# S32R372 register map
Vendor: Freescale Semiconductor, Inc.; Series: Qorivva; File version: 1.6
Registers are 32-bit, read-write, reset 0x0 unless marked. A register's access mark holds for its fields unless they carry their own. Offsets are from the block's base; [hi:lo] are bit positions; 'fields as' and 'values as' point back to an identical list.

## PMC
Base 0xFFFA0400; register names take the prefix PMC_
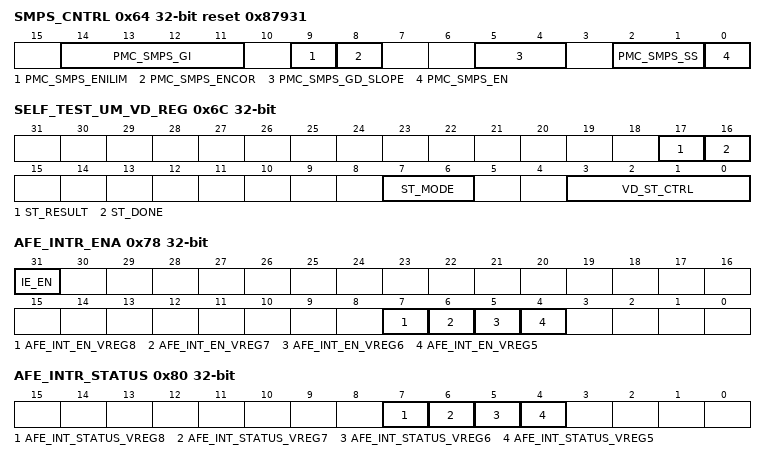
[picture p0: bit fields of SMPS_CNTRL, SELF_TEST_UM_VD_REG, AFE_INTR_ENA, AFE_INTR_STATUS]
0x64 SMPS_CNTRL reset 0x87931 — SMPS Control Register
  [14:11] PMC_SMPS_GI — SMPS Overshoot Current Trimming
  [9] PMC_SMPS_ENILIM — SMPS Inductor Current Limitation Enable
  [8] PMC_SMPS_ENCOR — SMPS Hysteretic Correction Enable
    0=Disabled; 1=Enabled
  [5:4] PMC_SMPS_GD_SLOPE — SMPS gate driver strength
    0=100% drive strength; 1=Approximately 70% drive strength; 2=Approximately 50% drive strength; 3=Approximately 35% drive strength
  [2:1] PMC_SMPS_SS — SMPS spread spectrum control
    0=No modulation; 1=15% modulation; 2=7.5% modulation; 3=30% modulation
  [0] PMC_SMPS_EN — SMPS controller enable
    0=SMPS control is disabled; 1=SMPS control is enabled
0x68 STTW reset 0xA0 — LVD Self Test Time Window Register
  [11:0] STTW — Self Test Time Window.
0x6C SELF_TEST_UM_VD_REG — Voltage Detect User Mode Test Register
  [17] ST_RESULT — ST_RESULT. Self Test result status.
    0=Self Test Failed; 1=Self Test Passed
  [16] ST_DONE ro — Self Test Done status.
    0=Self test running; 1=Self test completed
  [7:6] ST_MODE — Self Test mode bits for testing of LVDs and HVDs.
    0=Default; 1=Software triggered self test; 2=Single VD test as indicated by the VD_ST_CTRL bits
  [3:0] VD_ST_CTRL — Voltage Detect Self Test Control
    0=Functional Mode; 2=Core LVD; 3=Core HVD; 5=LVD PMC; 6=LVD Flash; 7=LVD ADC; 8=LVD PLL; 9=LVD IO; 10=HVD ADC
0x78 AFE_INTR_ENA — AFE Interrupt Enable Register
  [31] IE_EN — Interrupt Enable. This bit determines whether any of the Interrupt Enable bits can be written.
    0=No interrupt enables can be written; 1=Any interrupt enable can be written
  [7] AFE_INT_EN_VREG8 — AFE-8 Interrupt Enable/Disable Control: This field determines whether an interrupt is seen by the system
    0=No interrupt occurs; 1=An interrupt occurs
  [6] AFE_INT_EN_VREG7 — AFE-7 Interrupt Enable/Disable Control
    0=No interrupt occurs; 1=An interrupt occurs
  [5] AFE_INT_EN_VREG6 — AFE-6 Interrupt Enable/Disable Control
    0=No interrupt occurs; 1=An interrupt occurs
  [4] AFE_INT_EN_VREG5 — AFE-5 Interrupt Enable/Disable Control
    0=No interrupt occurs; 1=An interrupt occurs
0x80 AFE_INTR_STATUS — AFE Interrupt Status Register
  [7] AFE_INT_STATUS_VREG8 — AFE8-Interrupt Status: This bit indicates whether an Interrupt is seen by the system from AFE.
  [6] AFE_INT_STATUS_VREG7 — AFE7-Interrupt Status
    0=No Interrupt Occurrence has been detected; 1=An Interrupt occurrence has been detected
  [5] AFE_INT_STATUS_VREG6 — AFE6-Interrupt Status
    values as AFE_INT_STATUS_VREG7
  [4] AFE_INT_STATUS_VREG5 — AFE5-Interrupt Status
    values as AFE_INT_STATUS_VREG7
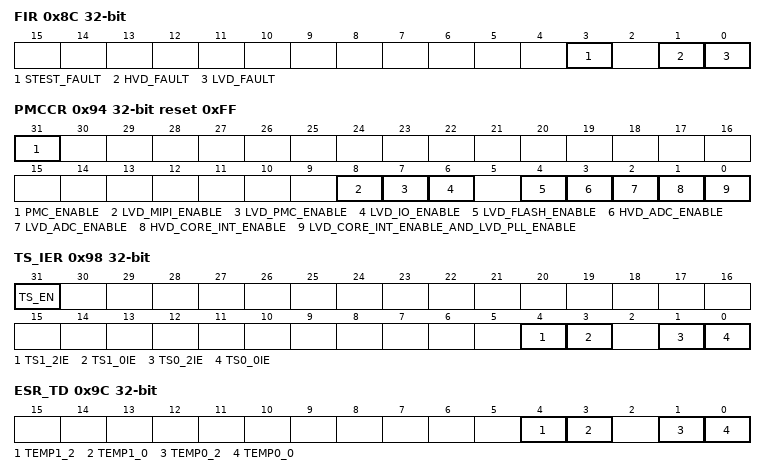
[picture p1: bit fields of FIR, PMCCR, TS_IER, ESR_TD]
0x8C FIR — FCCU Fault Injection Register
  [3] STEST_FAULT wo — A write to this bit sends a FCCU fault (single cycle) for LVD SELF TEST. This is self Clearing bit.
    0=No fault is sent; 1=Single cycle fault injected
  [1] HVD_FAULT wo — High Voltage Detect Fault injection.
    0=No fault is sent; 1=Single cycle fault injected
  [0] LVD_FAULT wo — Low Voltage Detect Fault injection.
    0=No fault is sent to FCCU; 1=Single cycle (one clock cycle) fault is injected to FCCU
0x94 PMCCR reset 0xFF — PMC Control Register
  [31] PMC_ENABLE — PMC Enable Control
    0=No control bit can be written in this(PMC enable control) register. To do a write on this register, first enable this bit and then start writing on other control bits.; 1=This Control register can be written
  [8] LVD_MIPI_ENABLE — This bit controls the enable/disable on the LVD MIPI supply.
    0=LVD_MIPI is disabled; 1=LVD_MIPI is enabled
  [7] LVD_PMC_ENABLE — This bit controls the enable/disable on the LVD PMC supply.
    0=LVD_PMC is disabled; 1=LVD_PMC is Enabled
  [6] LVD_IO_ENABLE — This bit controls the enable/disable on the LVD IO supply.
    0=LVD_IO is disabled; 1=LVD_IO is Enabled
  [4] LVD_FLASH_ENABLE — This bit controls the enable/disable on the LVD FLASH supply.
    0=LVD_FLASH is disabled; 1=LVD_FLASH is Enabled
  [3] HVD_ADC_ENABLE — This bit controls the enable/disable on the HVD ADC supply.
    0=HVD_ADC is disabled; 1=HVD_ADC is Enabled
  [2] LVD_ADC_ENABLE — This bit controls the enable/disable on the LVD ADC supply.
    0=LVD_ADC is disabled; 1=LVD_ADC is Enabled
  [1] HVD_CORE_INT_ENABLE — This bit controls the enable/disable on the HVD Core supply
    0=HVD_CORE is disabled; 1=HVD_CORE is Enabled
  [0] LVD_CORE_INT_ENABLE_AND_LVD_PLL_ENABLE — LVD Core and LVD_PLL Enable Disable control
    0=This Single bit does the control of LVD_CORE and LVD _PLL LVD_CORE_INT_ENABLE is disabled. LVD_PLL_ENABLE is disabled.; 1=LVD CORE_INT_ENABLE is Enabled. LVD_PLL_ENABLE is Enabled.
0x98 TS_IER — Interrupt Enable Register
  [31] TS_EN — Temperature Sensor interrupts Enable
    0=Temperature sensor interrupts are not enabled; 1=Enable temperature sensor interrupts
  [4] TS1_2IE — Temperature Sensor 1 input 2 Interrupt Enable.
    0=No interrupt; 1=Interrupt occurs
  [3] TS1_0IE — Temperature Sensor 1 input 0 Interrupt Enable.
    0=No interrupt; 1=Interrupt occurs
  [1] TS0_2IE — Temperature Sensor 0 input 2 Interrupt Enable.
    0=No interrupt; 1=Interrupt occurs
  [0] TS0_0IE — Temperature Sensor 0 input 0 Interrupt Enable.
    0=No interrupt; 1=Interrupt occurs
0x9C ESR_TD — Temperature Event Status register
  [all] fields
    0=Currently no occurrence; 1=Temperature occurrence detected
  [4] TEMP1_2 — Temperature sensor 1 status flag 2
  [3] TEMP1_0 — Temperature sensor 1 status flag 0
  [1] TEMP0_2 — Temperature sensor 0 status flag 2
  [0] TEMP0_0 — Temperature sensor 0 status flag 0
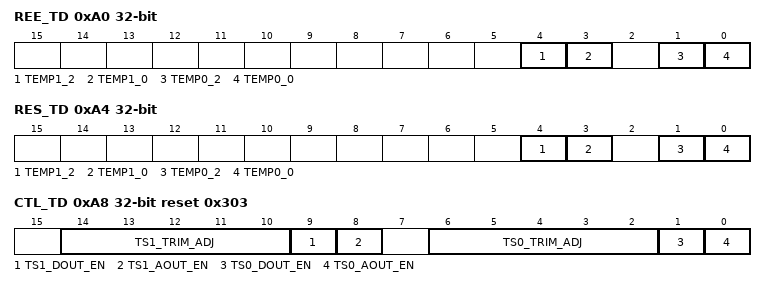
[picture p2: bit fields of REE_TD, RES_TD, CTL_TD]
0xA0 REE_TD — Temperature Reset Event Enable register
  [4] TEMP1_2 — Temperature sensor 1 detect assertion reset enable 2
  [3] TEMP1_0 — Temperature sensor 1 detect assertion reset enable 0
  [1] TEMP0_2 — Temperature sensor 0 detect assertion reset enable 2
  [0] TEMP0_0 — Temperature sensor 0 detect assertion reset enable 0
0xA4 RES_TD — Temperature Reset Event Selection register
  [4] TEMP1_2 — TEMP1_2 Reset Event Select
  [3] TEMP1_0 — TEMP1_0 Reset Event Select
  [1] TEMP0_2 — TEMP0_2 Reset Event Select
  [0] TEMP0_0 — TEMP0_0 Reset Event Select
0xA8 CTL_TD reset 0x303 — Temperature detector configuration register
  [14:10] TS1_TRIM_ADJ — Temperature Sensor 1 Trim Adjust value
  [9] TS1_DOUT_EN — Temperature Sensor 1 Digital Output Enable.
  [8] TS1_AOUT_EN — Temperature Sensor 1 Analog Output Enable. Analog Output Enable.
  [6:2] TS0_TRIM_ADJ — Temperature Sensor 0 Trim Adjust value
  [1] TS0_DOUT_EN — Temperature Sensor 1 Digital Output Enable.
  [0] TS0_AOUT_EN — Temperature Sensor 1 Analog Output Enable.
0xB4 TS_FIR — Fault Injection Register
  [0] TSNS_FAULT wo — Temperature Sensor Fault injection.
    0=No fault is sent; 1=Single cycle fault injected
